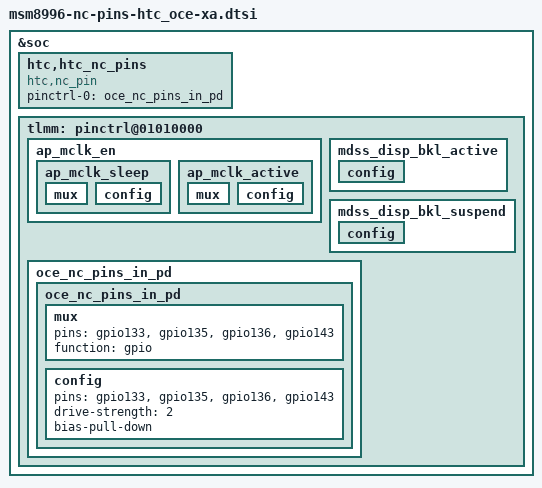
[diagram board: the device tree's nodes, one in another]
/* Copyright (c) 2016, The Linux Foundation. All rights reserved.
 *
 * This program is free software; you can redistribute it and/or modify
 * it under the terms of the GNU General Public License version 2 and
 * only version 2 as published by the Free Software Foundation.
 *
 * This program is distributed in the hope that it will be useful,
 * but WITHOUT ANY WARRANTY; without even the implied warranty of
 * MERCHANTABILITY or FITNESS FOR A PARTICULAR PURPOSE.  See the
 * GNU General Public License for more details.
 */

&soc {
	htc,htc_nc_pins {
		compatible = "htc,nc_pin";

		pinctrl-names = "default";
		pinctrl-0 = <&oce_nc_pins_in_pd>;
	};
};

&tlmm {
	oce_nc_pins_in_pd {
		oce_nc_pins_in_pd: oce_nc_pins_in_pd {
			mux {
				pins = "gpio133", "gpio135", "gpio136", "gpio143";
				function = "gpio";
			};

			config {
				pins = "gpio133", "gpio135", "gpio136", "gpio143";
				drive-strength = <2>;		/* 2 mA */
				bias-pull-down;			/* PULL DOWN */
			};
		};
	};

};

&soc {
	tlmm: pinctrl@01010000 {
		/* gpio133 */
		ap_mclk_en {
			ap_mclk_sleep: ap_mclk_sleep {
				mux {
					/delete-property/ pins;
				};

				config {
					/delete-property/ pins;
				};
			};
			ap_mclk_active: ap_mclk_active {
				mux {
					/delete-property/ pins;
				};

				config {
					/delete-property/ pins;
				};
			};
		};

		/* gpio135 */
		mdss_disp_bkl_active: mdss_disp_bkl_active {
			config {
				/delete-property/ pins;
			};
		};

		mdss_disp_bkl_suspend: mdss_disp_bkl_suspend {
			config {
				/delete-property/ pins;
			};
		};

		/* gpio136 */
		/* gpio143 */
	};
};
